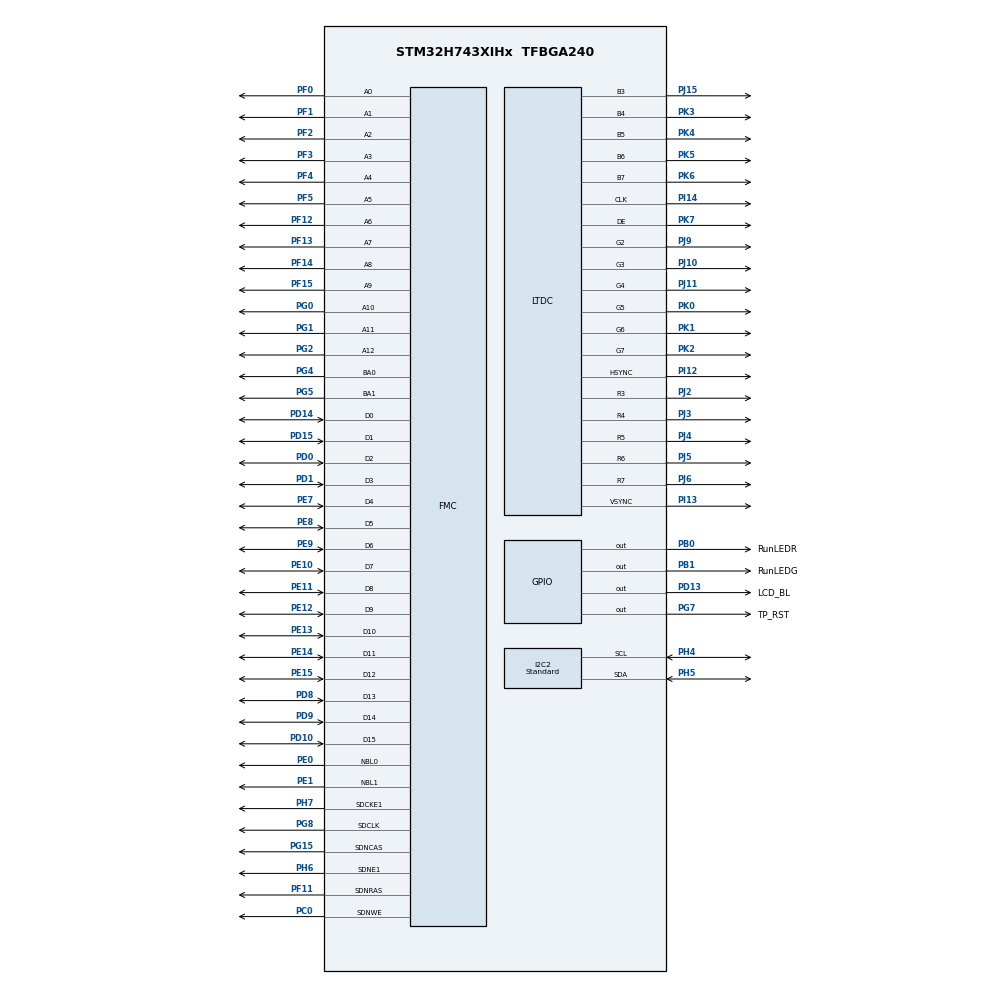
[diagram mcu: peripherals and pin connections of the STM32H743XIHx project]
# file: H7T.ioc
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CORTEX_M7.BaseAddress-Cortex_Memory_Protection_Unit_Region0_Settings=0xC0000000
CORTEX_M7.CPU_DCache=Disabled
CORTEX_M7.CPU_ICache=Disabled
CORTEX_M7.Enable-Cortex_Memory_Protection_Unit_Region0_Settings=MPU_REGION_ENABLE
CORTEX_M7.Enable-Cortex_Memory_Protection_Unit_Region1_Settings=__NULL
CORTEX_M7.IsBufferable-Cortex_Memory_Protection_Unit_Region0_Settings=MPU_ACCESS_BUFFERABLE
CORTEX_M7.IsCacheable-Cortex_Memory_Protection_Unit_Region0_Settings=MPU_ACCESS_CACHEABLE
CORTEX_M7.IsShareable-Cortex_Memory_Protection_Unit_Region0_Settings=MPU_ACCESS_SHAREABLE
CORTEX_M7.MPU_Control=__NULL
CORTEX_M7.Size-Cortex_Memory_Protection_Unit_Region0_Settings=MPU_REGION_SIZE_16MB
DMA2D.ColorMode=DMA2D_OUTPUT_RGB565
FMC.CASLatency1=FMC_SDRAM_CAS_LATENCY_3
FMC.ColumnBitsNumber1=FMC_SDRAM_COLUMN_BITS_NUM_9
FMC.ExitSelfRefreshDelay1=8
FMC.LoadToActiveDelay1=2
FMC.RCDDelay1=2
FMC.RPDelay1=2
FMC.ReadBurst1=FMC_SDRAM_RBURST_ENABLE
FMC.ReadPipeDelay1=FMC_SDRAM_RPIPE_DELAY_1
FMC.RowCycleDelay1=6
FMC.RowCycleDelay2=6
FMC.SDClockPeriod1=FMC_SDRAM_CLOCK_PERIOD_2
FMC.SelfRefreshTime1=5
FMC.WriteRecoveryTime1=3
FREERTOS.Tasks01=defaultTask,24,1024,StartDefaultTask,Default,NULL,Dynamic,NULL,NULL
FREERTOS.configUSE_TICK_HOOK=1
I2C2.I2C_Speed_Mode=I2C_Standard
I2C2.Timing=0x307075B1
LTDC.ActiveW=800
LTDC.Alpha_L0=255
LTDC.Alpha_L1=255
LTDC.BlendingFactor1_L0=LTDC_BLENDING_FACTOR1_CA
LTDC.BlendingFactor2_L0=LTDC_BLENDING_FACTOR2_CA
LTDC.Blue_L0=255
LTDC.Blue_L1=0
LTDC.FBStartAdress_L0=0xD0000000
LTDC.Green_L1=255
LTDC.HBP=46
LTDC.HFP=13
LTDC.HSync=1
LTDC.ImageHeight_L0=480
LTDC.ImageWidth_L0=800
LTDC.Layers=0
LTDC.PixelFormat_L0=LTDC_PIXEL_FORMAT_RGB565
LTDC.VBP=23
LTDC.VFP=13
LTDC.VSync=3
LTDC.WindowX1_L0=800
LTDC.WindowX1_L1=800
LTDC.WindowY1_L0=480
LTDC.WindowY1_L1=480
Mcu.Family=STM32H7
Mcu.Name=STM32H743XIHx
Mcu.Package=TFBGA240
NVIC.DMA2D_IRQn=true\:5\:0\:false\:false\:true\:true\:true\:true
NVIC.PriorityGroup=NVIC_PRIORITYGROUP_4
NVIC.TIM6_DAC_IRQn=true\:15\:0\:false\:false\:true\:false\:false\:true
NVIC.TimeBase=TIM6_DAC_IRQn
NVIC.TimeBaseIP=TIM6
PA10.Signal=USART1_RX
PA13\ (JTMS/SWDIO).Mode=Serial_Wire
PA13\ (JTMS/SWDIO).Signal=DEBUG_JTMS-SWDIO
PA14\ (JTCK/SWCLK).Mode=Serial_Wire
PA14\ (JTCK/SWCLK).Signal=DEBUG_JTCK-SWCLK
PA9.Signal=USART1_TX
PB0.GPIO_Label=RunLEDR
PB0.Signal=GPIO_Output
PB1.GPIO_Label=RunLEDG
PB1.Signal=GPIO_Output
PC0.Signal=FMC_SDNWE
PD0.Signal=FMC_D2_DA2
PD1.Signal=FMC_D3_DA3
PD10.Signal=FMC_D15_DA15
PD13.GPIO_Label=LCD_BL
PD13.PinState=GPIO_PIN_SET
PD13.Signal=GPIO_Output
PD14.Signal=FMC_D0_DA0
PD15.Signal=FMC_D1_DA1
PD8.Signal=FMC_D13_DA13
PD9.Signal=FMC_D14_DA14
PE0.Signal=FMC_NBL0
PE1.Signal=FMC_NBL1
PE10.Signal=FMC_D7_DA7
PE11.Signal=FMC_D8_DA8
PE12.Signal=FMC_D9_DA9
PE13.Signal=FMC_D10_DA10
PE14.Signal=FMC_D11_DA11
PE15.Signal=FMC_D12_DA12
PE7.Signal=FMC_D4_DA4
PE8.Signal=FMC_D5_DA5
PE9.Signal=FMC_D6_DA6
PF0.Signal=FMC_A0
PF1.Signal=FMC_A1
PF11.Signal=FMC_SDNRAS
PF12.Signal=FMC_A6
PF13.Signal=FMC_A7
PF14.Signal=FMC_A8
PF15.Signal=FMC_A9
PF2.Signal=FMC_A2
PF3.Signal=FMC_A3
PF4.Signal=FMC_A4
PF5.Signal=FMC_A5
PG0.Signal=FMC_A10
PG1.Signal=FMC_A11
PG15.Signal=FMC_SDNCAS
PG2.Signal=FMC_A12
PG4.Signal=FMC_A14_BA0
PG5.Signal=FMC_A15_BA1
PG7.GPIO_Label=TP_RST
PG7.PinState=GPIO_PIN_SET
PG7.Signal=GPIO_Output
PG8.Signal=FMC_SDCLK
PH0-OSC_IN\ (PH0).Mode=HSE-External-Oscillator
PH0-OSC_IN\ (PH0).Signal=RCC_OSC_IN
PH1-OSC_OUT\ (PH1).Mode=HSE-External-Oscillator
PH1-OSC_OUT\ (PH1).Signal=RCC_OSC_OUT
PH4.Mode=I2C
PH4.Signal=I2C2_SCL
PH5.Mode=I2C
PH5.Signal=I2C2_SDA
PH6.Mode=SdramChipSelect2_1
PH6.Signal=FMC_SDNE1
PH7.Mode=SdramChipSelect2_1
PH7.Signal=FMC_SDCKE1
PI12.GPIO_Speed=GPIO_SPEED_FREQ_VERY_HIGH
PI12.Mode=RGB565
PI12.Signal=LTDC_HSYNC
PI13.GPIO_Speed=GPIO_SPEED_FREQ_VERY_HIGH
PI13.Mode=RGB565
PI13.Signal=LTDC_VSYNC
PI14.GPIO_Speed=GPIO_SPEED_FREQ_VERY_HIGH
PI14.Mode=RGB565
PI14.Signal=LTDC_CLK
PJ10.GPIO_Speed=GPIO_SPEED_FREQ_VERY_HIGH
PJ10.Mode=RGB565
PJ10.Signal=LTDC_G3
PJ11.GPIO_Speed=GPIO_SPEED_FREQ_VERY_HIGH
PJ11.Mode=RGB565
PJ11.Signal=LTDC_G4
PJ15.GPIO_Speed=GPIO_SPEED_FREQ_VERY_HIGH
PJ15.Mode=RGB565
PJ15.Signal=LTDC_B3
PJ2.GPIO_Speed=GPIO_SPEED_FREQ_VERY_HIGH
PJ2.Mode=RGB565
PJ2.Signal=LTDC_R3
PJ3.GPIO_Speed=GPIO_SPEED_FREQ_VERY_HIGH
PJ3.Mode=RGB565
PJ3.Signal=LTDC_R4
PJ4.GPIO_Speed=GPIO_SPEED_FREQ_VERY_HIGH
PJ4.Mode=RGB565
PJ4.Signal=LTDC_R5
PJ5.GPIO_Speed=GPIO_SPEED_FREQ_VERY_HIGH
PJ5.Mode=RGB565
PJ5.Signal=LTDC_R6
PJ6.GPIO_Speed=GPIO_SPEED_FREQ_VERY_HIGH
PJ6.Mode=RGB565
PJ6.Signal=LTDC_R7
PJ9.GPIO_Speed=GPIO_SPEED_FREQ_VERY_HIGH
PJ9.Mode=RGB565
PJ9.Signal=LTDC_G2
PK0.GPIO_Speed=GPIO_SPEED_FREQ_VERY_HIGH
PK0.Mode=RGB565
PK0.Signal=LTDC_G5
PK1.GPIO_Speed=GPIO_SPEED_FREQ_VERY_HIGH
PK1.Mode=RGB565
PK1.Signal=LTDC_G6
PK2.GPIO_Speed=GPIO_SPEED_FREQ_VERY_HIGH
PK2.Mode=RGB565
PK2.Signal=LTDC_G7
PK3.GPIO_Speed=GPIO_SPEED_FREQ_VERY_HIGH
PK3.Mode=RGB565
PK3.Signal=LTDC_B4
PK4.GPIO_Speed=GPIO_SPEED_FREQ_VERY_HIGH
PK4.Mode=RGB565
PK4.Signal=LTDC_B5
PK5.GPIO_Speed=GPIO_SPEED_FREQ_VERY_HIGH
PK5.Mode=RGB565
PK5.Signal=LTDC_B6
PK6.GPIO_Speed=GPIO_SPEED_FREQ_VERY_HIGH
PK6.Mode=RGB565
PK6.Signal=LTDC_B7
PK7.GPIO_Speed=GPIO_SPEED_FREQ_VERY_HIGH
PK7.Mode=RGB565
PK7.Signal=LTDC_DE
ProjectManager.HeapSize=0x200
ProjectManager.StackSize=0x400
ProjectManager.TargetToolchain=MDK-ARM V5.32
RCC.ADCFreq_Value=75000000
RCC.APB1Freq_Value=120000000
RCC.APB2Freq_Value=120000000
RCC.APB3Freq_Value=120000000
RCC.APB4Freq_Value=120000000
RCC.CortexFreq_Value=480000000
RCC.D1PPRE=RCC_APB3_DIV2
RCC.D2PPRE1=RCC_APB1_DIV2
RCC.D2PPRE2=RCC_APB2_DIV2
RCC.D3PPRE=RCC_APB4_DIV2
RCC.DIVM1=5
RCC.DIVM2=2
RCC.DIVM3=1
RCC.DIVN1=192
RCC.DIVN2=12
RCC.DIVN3=30
RCC.DIVR2=1
RCC.DIVR3=15
RCC.HCLKFreq_Value=240000000
RCC.HPRE=RCC_HCLK_DIV2
RCC.PLL2FRACN=0
RCC.PLL3FRACN=0
RCC.PLLFRACN=0
RCC.PLLSourceVirtual=RCC_PLLSOURCE_HSE
RCC.PWR_Regulator_Voltage_Scale=PWR_REGULATOR_VOLTAGE_SCALE0
RCC.SYSCLKFreq_VALUE=480000000
RCC.SYSCLKSource=RCC_SYSCLKSOURCE_PLLCLK
RCC.USBFreq_Value=480000000
SH.FMC_A0.0=FMC_A0,13b-sda1
SH.FMC_A1.0=FMC_A1,13b-sda1
SH.FMC_A10.0=FMC_A10,13b-sda1
SH.FMC_A11.0=FMC_A11,13b-sda1
SH.FMC_A12.0=FMC_A12,13b-sda1
SH.FMC_A14_BA0.0=FMC_BA0,FourSdramBanks1
SH.FMC_A15_BA1.0=FMC_BA1,FourSdramBanks1
SH.FMC_A2.0=FMC_A2,13b-sda1
SH.FMC_A3.0=FMC_A3,13b-sda1
SH.FMC_A4.0=FMC_A4,13b-sda1
SH.FMC_A5.0=FMC_A5,13b-sda1
SH.FMC_A6.0=FMC_A6,13b-sda1
SH.FMC_A7.0=FMC_A7,13b-sda1
SH.FMC_A8.0=FMC_A8,13b-sda1
SH.FMC_A9.0=FMC_A9,13b-sda1
SH.FMC_D0_DA0.0=FMC_D0,sd-16b-d1
SH.FMC_D10_DA10.0=FMC_D10,sd-16b-d1
SH.FMC_D11_DA11.0=FMC_D11,sd-16b-d1
SH.FMC_D12_DA12.0=FMC_D12,sd-16b-d1
SH.FMC_D13_DA13.0=FMC_D13,sd-16b-d1
SH.FMC_D14_DA14.0=FMC_D14,sd-16b-d1
SH.FMC_D15_DA15.0=FMC_D15,sd-16b-d1
SH.FMC_D1_DA1.0=FMC_D1,sd-16b-d1
SH.FMC_D2_DA2.0=FMC_D2,sd-16b-d1
SH.FMC_D3_DA3.0=FMC_D3,sd-16b-d1
SH.FMC_D4_DA4.0=FMC_D4,sd-16b-d1
SH.FMC_D5_DA5.0=FMC_D5,sd-16b-d1
SH.FMC_D6_DA6.0=FMC_D6,sd-16b-d1
SH.FMC_D7_DA7.0=FMC_D7,sd-16b-d1
SH.FMC_D8_DA8.0=FMC_D8,sd-16b-d1
SH.FMC_D9_DA9.0=FMC_D9,sd-16b-d1
SH.FMC_NBL0.0=FMC_NBL0,Sd2ByteEnable1
SH.FMC_NBL1.0=FMC_NBL1,Sd2ByteEnable1
SH.FMC_SDCLK.0=FMC_SDCLK,13b-sda1
SH.FMC_SDNCAS.0=FMC_SDNCAS,13b-sda1
SH.FMC_SDNRAS.0=FMC_SDNRAS,13b-sda1
SH.FMC_SDNWE.0=FMC_SDNWE,13b-sda1
VP_DMA2D_VS_DMA2D.Mode=DMA2D_Activate
VP_FREERTOS_VS_CMSIS_V2.Mode=CMSIS_V2
VP_SYS_VS_tim6.Mode=TIM6
board=custom

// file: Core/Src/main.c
/* USER CODE BEGIN Header */
/* USER CODE END Header */
#include "main.h"
#include "cmsis_os.h"
#include "dma2d.h"
#include "i2c.h"
#include "ltdc.h"
#include "gpio.h"
#include "fmc.h"

/* USER CODE BEGIN Includes */
#include "sdram_fmc_drv.h"
#include "lcd_rgb_ltdc_drv.h"
#include "GT9157.h"
#include "stdio.h"
/* USER CODE END Includes */

/* USER CODE BEGIN PV */

    uint8_t pucBuff[64] = {0};
/* USER CODE END PV */

void SystemClock_Config(void);
void MX_FREERTOS_Init(void);

int main(void)
{
  /* USER CODE BEGIN 1 */
    uint8_t temp = 0, data[4];
    int16_t x, y;
  /* USER CODE END 1 */

  /* MCU Configuration--------------------------------------------------------*/

  /* Reset of all peripherals, Initializes the Flash interface and the Systick. */
  HAL_Init();

  /* Configure the system clock */
  SystemClock_Config();

  /* USER CODE BEGIN SysInit */
  MX_GPIO_Init();
  MX_FMC_Init();
  MX_LTDC_Init();
  MX_DMA2D_Init();
  MX_I2C2_Init();
  /* 初始化触摸屏 */
  GTP_Init_Panel();
#if 0
  /* USER CODE END SysInit */

  /* Initialize all configured peripherals */
  MX_GPIO_Init();
  MX_LTDC_Init();
  MX_FMC_Init();
  MX_DMA2D_Init();
  MX_I2C2_Init();
  /* USER CODE BEGIN 2 */
#endif
//    lcd_clear(WHITE);
//  while(1){
//      GT911_ReadReg(GT_GSTID_REG, &temp, 1);
//      HAL_Delay(10);
//
//        if (temp & 0x80) {
//            if(temp & 0x0F){
//                  GT911_ReadReg(GT_TP1_REG, data, 4);
//                    y = ((data[1] & 0x0f) << 8) + data[0];
//                    x = (((data[3] & 0x0f) << 8) + data[2]);
//            }
//        }
//
//      sprintf((char *)pucBuff, "char:%2x,x:%3d,y:%3d  ", temp, x, y);
//      LCD_DisplayStringAt(0, 0, pucBuff, 0);
//        temp = 0;
//        GT911_WriteReg(GT_GSTID_REG, &temp, 1);
//      HAL_Delay(1);
//  }
  /* USER CODE END 2 */

  /* Init scheduler */
  osKernelInitialize();  /* Call init function for freertos objects (in freertos.c) */
  MX_FREERTOS_Init();
  /* Start scheduler */
  osKernelStart();

  /* We should never get here as control is now taken by the scheduler */
  /* Infinite loop */
  while(1)
  {

  }
}

void SystemClock_Config(void)
{
  RCC_OscInitTypeDef RCC_OscInitStruct = {0};
  RCC_ClkInitTypeDef RCC_ClkInitStruct = {0};

  /** Supply configuration update enable
  */
  HAL_PWREx_ConfigSupply(PWR_LDO_SUPPLY);
  /** Configure the main internal regulator output voltage
  */
  __HAL_PWR_VOLTAGESCALING_CONFIG(PWR_REGULATOR_VOLTAGE_SCALE0);

  while(!__HAL_PWR_GET_FLAG(PWR_FLAG_VOSRDY)) {}
  /** Macro to configure the PLL clock source
  */
  __HAL_RCC_PLL_PLLSOURCE_CONFIG(RCC_PLLSOURCE_HSE);
  /** Initializes the RCC Oscillators according to the specified parameters
  * in the RCC_OscInitTypeDef structure.
  */
  RCC_OscInitStruct.OscillatorType = RCC_OSCILLATORTYPE_HSE;
  RCC_OscInitStruct.HSEState = RCC_HSE_ON;
  RCC_OscInitStruct.PLL.PLLState = RCC_PLL_ON;
  RCC_OscInitStruct.PLL.PLLSource = RCC_PLLSOURCE_HSE;
  RCC_OscInitStruct.PLL.PLLM = 5;
  RCC_OscInitStruct.PLL.PLLN = 192;
  RCC_OscInitStruct.PLL.PLLP = 2;
  RCC_OscInitStruct.PLL.PLLQ = 2;
  RCC_OscInitStruct.PLL.PLLR = 2;
  RCC_OscInitStruct.PLL.PLLRGE = RCC_PLL1VCIRANGE_2;
  RCC_OscInitStruct.PLL.PLLVCOSEL = RCC_PLL1VCOWIDE;
  RCC_OscInitStruct.PLL.PLLFRACN = 0;
  if (HAL_RCC_OscConfig(&RCC_OscInitStruct) != HAL_OK)
  {
    Error_Handler();
  }
  /** Initializes the CPU, AHB and APB buses clocks
  */
  RCC_ClkInitStruct.ClockType = RCC_CLOCKTYPE_HCLK|RCC_CLOCKTYPE_SYSCLK
                              |RCC_CLOCKTYPE_PCLK1|RCC_CLOCKTYPE_PCLK2
                              |RCC_CLOCKTYPE_D3PCLK1|RCC_CLOCKTYPE_D1PCLK1;
  RCC_ClkInitStruct.SYSCLKSource = RCC_SYSCLKSOURCE_PLLCLK;
  RCC_ClkInitStruct.SYSCLKDivider = RCC_SYSCLK_DIV1;
  RCC_ClkInitStruct.AHBCLKDivider = RCC_HCLK_DIV2;
  RCC_ClkInitStruct.APB3CLKDivider = RCC_APB3_DIV2;
  RCC_ClkInitStruct.APB1CLKDivider = RCC_APB1_DIV2;
  RCC_ClkInitStruct.APB2CLKDivider = RCC_APB2_DIV2;
  RCC_ClkInitStruct.APB4CLKDivider = RCC_APB4_DIV2;

  if (HAL_RCC_ClockConfig(&RCC_ClkInitStruct, FLASH_LATENCY_4) != HAL_OK)
  {
    Error_Handler();
  }
}

void HAL_TIM_PeriodElapsedCallback(TIM_HandleTypeDef *htim)
{
  if (htim->Instance == TIM6) {
    HAL_IncTick();
  }
}

void Error_Handler(void)
{
}

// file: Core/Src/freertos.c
/* USER CODE BEGIN Header */
/**
  ******************************************************************************
  * File Name          : freertos.c
  * Description        : Code for freertos applications
  ******************************************************************************
  * @attention
  *
  * Copyright (c) 2024 STMicroelectronics.
  * All rights reserved.
  *
  * This software is licensed under terms that can be found in the LICENSE file
  * in the root directory of this software component.
  * If no LICENSE file comes with this software, it is provided AS-IS.
  *
  ******************************************************************************
  */
/* USER CODE END Header */

#include "FreeRTOS.h"
#include "task.h"
#include "main.h"
#include "cmsis_os.h"

/* USER CODE BEGIN Includes */

#include "lcd_rgb_ltdc_drv.h"
#include "lvgl.h"
#include "lv_port_disp_template.h"
#include "lv_port_indev_template.h"
#include "gui_guider.h"
#include "events_init.h"
/* USER CODE END Includes */

/* USER CODE BEGIN Variables */
lv_ui guider_ui;
/* USER CODE END Variables */
/* Definitions for defaultTask */
osThreadId_t defaultTaskHandle;
const osThreadAttr_t defaultTask_attributes = {
  .name = "defaultTask",
  .stack_size = 1024 * 4,
  .priority = (osPriority_t) osPriorityNormal,
};

void StartDefaultTask(void *argument);

void MX_FREERTOS_Init(void); /* (MISRA C 2004 rule 8.1) */

///* Hook prototypes */
//void vApplicationTickHook(void);

///* USER CODE BEGIN 3 */
//void vApplicationTickHook( void )
//{
//   /* This function will be called by each tick interrupt if
//   configUSE_TICK_HOOK is set to 1 in FreeRTOSConfig.h. User code can be
//   added here, but the tick hook is called from an interrupt context, so
//   code must not attempt to block, and only the interrupt safe FreeRTOS API
//   functions can be used (those that end in FromISR()). */
//}
/* USER CODE END 3 */

void MX_FREERTOS_Init(void) {

  /* Create the thread(s) */
  /* creation of defaultTask */
  defaultTaskHandle = osThreadNew(StartDefaultTask, NULL, &defaultTask_attributes);

}

void StartDefaultTask(void *argument)
{
  /* USER CODE BEGIN StartDefaultTask */
    lv_init();
	lv_port_disp_init();
	lv_port_indev_init();
//	lv_obj_t* btn = lv_btn_create(lv_scr_act());
//	lv_obj_set_pos(btn, 0, 0);
//	lv_obj_set_size(btn, 120, 50);
//	lv_obj_t* label = lv_label_create(btn);
//	lv_label_set_text(label, "Button");
//	lv_obj_center(label);

//	lv_obj_t* slider1 = lv_slider_create(lv_scr_act());
//    lv_obj_set_pos(slider1,100,100);
//    lv_slider_set_value(slider1, 80, LV_ANIM_OFF);
    setup_ui(&guider_ui);
    events_init(&guider_ui);
  /* Infinite loop */
  for(;;)
  {
//    lcd_clear(RED);
//		osDelay(1000);
//  lcd_clear(BLUE);
//		osDelay(1000);
//  lcd_clear(YELLOW);
//		osDelay(1000);
    lv_timer_handler();

    osDelay(5);
  }
  /* USER CODE END StartDefaultTask */
}
